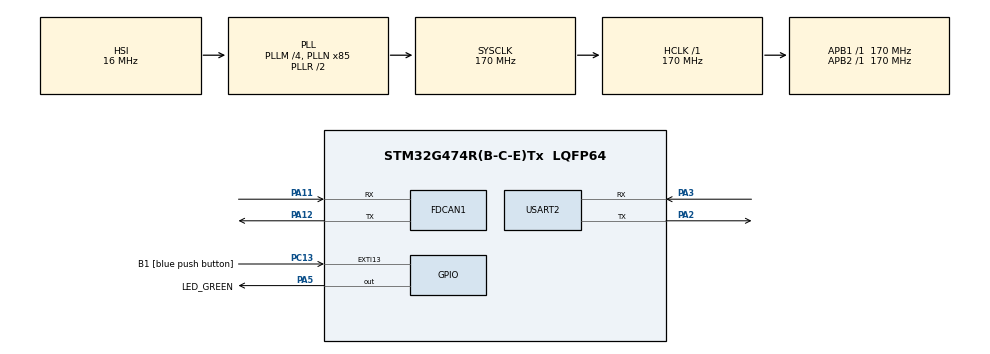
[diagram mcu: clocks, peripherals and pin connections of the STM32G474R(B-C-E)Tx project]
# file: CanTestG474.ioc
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FDCAN1.CalculateBaudRateNominal=100117
FDCAN1.CalculateTimeBitNominal=9988
FDCAN1.CalculateTimeQuantumNominal=3329.4117647058824
FDCAN1.ClockDivider=FDCAN_CLOCK_DIV2
FDCAN1.NominalPrescaler=283
FREERTOS.Tasks01=defaultTask,24,128,StartDefaultTask,Default,NULL,Dynamic,NULL,NULL
Mcu.Family=STM32G4
Mcu.Name=STM32G474R(B-C-E)Tx
Mcu.Package=LQFP64
NVIC.EXTI15_10_IRQn=true\:5\:0\:false\:false\:true\:true\:true\:true\:true
NVIC.FDCAN1_IT0_IRQn=true\:5\:0\:false\:false\:true\:true\:true\:true\:true
NVIC.FDCAN1_IT1_IRQn=true\:5\:0\:false\:false\:true\:true\:true\:true\:true
NVIC.PriorityGroup=NVIC_PRIORITYGROUP_4
NVIC.TIM6_DAC_IRQn=true\:15\:0\:false\:false\:true\:false\:false\:true\:true
NVIC.TimeBase=TIM6_DAC_IRQn
NVIC.TimeBaseIP=TIM6
PA11.GPIO_PuPd=GPIO_PULLUP
PA11.GPIO_Speed=GPIO_SPEED_FREQ_VERY_HIGH
PA11.Mode=FDCAN_Activate
PA11.Signal=FDCAN1_RX
PA12.GPIO_PuPd=GPIO_PULLUP
PA12.GPIO_Speed=GPIO_SPEED_FREQ_VERY_HIGH
PA12.Mode=FDCAN_Activate
PA12.Signal=FDCAN1_TX
PA13.GPIO_Label=T_SWDIO
PA13.Mode=Trace_Asynchronous_SW
PA13.Signal=SYS_JTMS-SWDIO
PA14.GPIO_Label=T_SWCLK
PA14.Mode=Trace_Asynchronous_SW
PA14.Signal=SYS_JTCK-SWCLK
PA2.Mode=Asynchronous
PA2.Signal=USART2_TX
PA3.Mode=Asynchronous
PA3.Signal=USART2_RX
PA5.GPIO_Label=LED_GREEN
PA5.Signal=GPIO_Output
PB3.GPIO_Label=T_SWO
PB3.Mode=Trace_Asynchronous_SW
PB3.Signal=SYS_JTDO-SWO
PC13.GPIO_Label=B1 [blue push button]
PC13.Signal=GPXTI13
PC14-OSC32_IN.GPIO_Label=RCC_OSC32_IN
PC14-OSC32_IN.Signal=RCC_OSC32_IN
PC15-OSC32_OUT.GPIO_Label=RCC_OSC32_OUT
PC15-OSC32_OUT.Signal=RCC_OSC32_OUT
PF0-OSC_IN.GPIO_Label=RCC_OSC_IN
PF0-OSC_IN.Signal=RCC_OSC_IN
PF1-OSC_OUT.GPIO_Label=RCC_OSC_OUT
PF1-OSC_OUT.Signal=RCC_OSC_OUT
ProjectManager.HeapSize=0x200
ProjectManager.StackSize=0x400
ProjectManager.TargetToolchain=STM32CubeIDE
RCC.ADC12Freq_Value=170000000
RCC.ADC345Freq_Value=170000000
RCC.AHBFreq_Value=170000000
RCC.APB1Freq_Value=170000000
RCC.APB1TimFreq_Value=170000000
RCC.APB2Freq_Value=170000000
RCC.APB2TimFreq_Value=170000000
RCC.CortexFreq_Value=170000000
RCC.EXTERNAL_CLOCK_VALUE=12288000
RCC.HCLKFreq_Value=170000000
RCC.HSE_VALUE=24000000
RCC.HSI48_VALUE=48000000
RCC.HSI_VALUE=16000000
RCC.LSE_VALUE=32768
RCC.PLLM=RCC_PLLM_DIV4
RCC.PLLN=85
RCC.RTCClockSelection=RCC_RTCCLKSOURCE_LSE
RCC.SYSCLKFreq_VALUE=170000000
RCC.SYSCLKSource=RCC_SYSCLKSOURCE_PLLCLK
RCC.USBFreq_Value=170000000
RCC.VCOOutputFreq_Value=340000000
USART2.VirtualMode-Asynchronous=VM_ASYNC
VP_FREERTOS_VS_CMSIS_V2.Mode=CMSIS_V2
VP_SYS_VS_DBSignals.Mode=DisableDeadBatterySignals
VP_SYS_VS_tim6.Mode=TIM6
board=NUCLEO-G474RE

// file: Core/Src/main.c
/* USER CODE BEGIN Header */
/**
  ******************************************************************************
  * @file           : main.c
  * @brief          : Main program body
  ******************************************************************************
  * @attention
  *
  * Copyright (c) 2024 STMicroelectronics.
  * All rights reserved.
  *
  * This software is licensed under terms that can be found in the LICENSE file
  * in the root directory of this software component.
  * If no LICENSE file comes with this software, it is provided AS-IS.
  *
  ******************************************************************************
  */
/* USER CODE END Header */
#include "main.h"
#include "cmsis_os.h"

/* USER CODE BEGIN Includes */

#include <stdio.h>
#include <string.h>

/* USER CODE END Includes */

FDCAN_HandleTypeDef hfdcan1;

UART_HandleTypeDef huart2;

/* Definitions for defaultTask */
osThreadId_t defaultTaskHandle;
const osThreadAttr_t defaultTask_attributes = {
  .name = "defaultTask",
  .priority = (osPriority_t) osPriorityNormal,
  .stack_size = 128 * 4
};

void SystemClock_Config(void);
static void MX_GPIO_Init(void);
static void MX_FDCAN1_Init(void);
static void MX_USART2_UART_Init(void);
void StartDefaultTask(void *argument);

/* USER CODE BEGIN 0 */

int _write(int file, char *data, int len)
{
	HAL_UART_Transmit(&huart2, (uint8_t*)data, len, 100);
	return len;
}

/* USER CODE END 0 */

int main(void)
{

  /* MCU Configuration--------------------------------------------------------*/

  /* Reset of all peripherals, Initializes the Flash interface and the Systick. */
  HAL_Init();

  /* Configure the system clock */
  SystemClock_Config();

  /* Initialize all configured peripherals */
  MX_GPIO_Init();
  MX_FDCAN1_Init();
  MX_USART2_UART_Init();

  /* Init scheduler */
  osKernelInitialize();

  /* Create the thread(s) */
  /* creation of defaultTask */
  defaultTaskHandle = osThreadNew(StartDefaultTask, NULL, &defaultTask_attributes);

  /* Start scheduler */
  osKernelStart();

  /* We should never get here as control is now taken by the scheduler */

  /* Infinite loop */
  while (1)
  {

  }
}

void SystemClock_Config(void)
{
  RCC_OscInitTypeDef RCC_OscInitStruct = {0};
  RCC_ClkInitTypeDef RCC_ClkInitStruct = {0};

  /** Configure the main internal regulator output voltage
  */
  HAL_PWREx_ControlVoltageScaling(PWR_REGULATOR_VOLTAGE_SCALE1_BOOST);

  /** Initializes the RCC Oscillators according to the specified parameters
  * in the RCC_OscInitTypeDef structure.
  */
  RCC_OscInitStruct.OscillatorType = RCC_OSCILLATORTYPE_HSI;
  RCC_OscInitStruct.HSIState = RCC_HSI_ON;
  RCC_OscInitStruct.HSICalibrationValue = RCC_HSICALIBRATION_DEFAULT;
  RCC_OscInitStruct.PLL.PLLState = RCC_PLL_ON;
  RCC_OscInitStruct.PLL.PLLSource = RCC_PLLSOURCE_HSI;
  RCC_OscInitStruct.PLL.PLLM = RCC_PLLM_DIV4;
  RCC_OscInitStruct.PLL.PLLN = 85;
  RCC_OscInitStruct.PLL.PLLP = RCC_PLLP_DIV2;
  RCC_OscInitStruct.PLL.PLLQ = RCC_PLLQ_DIV2;
  RCC_OscInitStruct.PLL.PLLR = RCC_PLLR_DIV2;
  if (HAL_RCC_OscConfig(&RCC_OscInitStruct) != HAL_OK)
  {
    Error_Handler();
  }

  /** Initializes the CPU, AHB and APB buses clocks
  */
  RCC_ClkInitStruct.ClockType = RCC_CLOCKTYPE_HCLK|RCC_CLOCKTYPE_SYSCLK
                              |RCC_CLOCKTYPE_PCLK1|RCC_CLOCKTYPE_PCLK2;
  RCC_ClkInitStruct.SYSCLKSource = RCC_SYSCLKSOURCE_PLLCLK;
  RCC_ClkInitStruct.AHBCLKDivider = RCC_SYSCLK_DIV1;
  RCC_ClkInitStruct.APB1CLKDivider = RCC_HCLK_DIV1;
  RCC_ClkInitStruct.APB2CLKDivider = RCC_HCLK_DIV1;

  if (HAL_RCC_ClockConfig(&RCC_ClkInitStruct, FLASH_LATENCY_4) != HAL_OK)
  {
    Error_Handler();
  }
}

static void MX_FDCAN1_Init(void)
{

  hfdcan1.Instance = FDCAN1;
  hfdcan1.Init.ClockDivider = FDCAN_CLOCK_DIV2;
  hfdcan1.Init.FrameFormat = FDCAN_FRAME_CLASSIC;
  hfdcan1.Init.Mode = FDCAN_MODE_NORMAL;
  hfdcan1.Init.AutoRetransmission = DISABLE;
  hfdcan1.Init.TransmitPause = DISABLE;
  hfdcan1.Init.ProtocolException = DISABLE;
  hfdcan1.Init.NominalPrescaler = 283;
  hfdcan1.Init.NominalSyncJumpWidth = 1;
  hfdcan1.Init.NominalTimeSeg1 = 1;
  hfdcan1.Init.NominalTimeSeg2 = 1;
  hfdcan1.Init.DataPrescaler = 1;
  hfdcan1.Init.DataSyncJumpWidth = 1;
  hfdcan1.Init.DataTimeSeg1 = 1;
  hfdcan1.Init.DataTimeSeg2 = 1;
  hfdcan1.Init.StdFiltersNbr = 0;
  hfdcan1.Init.ExtFiltersNbr = 0;
  hfdcan1.Init.TxFifoQueueMode = FDCAN_TX_FIFO_OPERATION;
  if (HAL_FDCAN_Init(&hfdcan1) != HAL_OK)
  {
    Error_Handler();
  }
  /* USER CODE BEGIN FDCAN1_Init 2 */

  FDCAN_FilterTypeDef canFilterConfig;
  canFilterConfig.IdType = FDCAN_STANDARD_ID;
  canFilterConfig.FilterIndex = 0;
  canFilterConfig.FilterType = FDCAN_FILTER_RANGE;
  canFilterConfig.FilterConfig = FDCAN_FILTER_TO_RXFIFO0;
  canFilterConfig.FilterID1 = 0x000;
  canFilterConfig.FilterID2 = 0x010;

  if (HAL_FDCAN_ConfigFilter(&hfdcan1, &canFilterConfig) != HAL_OK)
  {
	  Error_Handler();
  }

  /* USER CODE END FDCAN1_Init 2 */

}

static void MX_USART2_UART_Init(void)
{

  huart2.Instance = USART2;
  huart2.Init.BaudRate = 115200;
  huart2.Init.WordLength = UART_WORDLENGTH_8B;
  huart2.Init.StopBits = UART_STOPBITS_1;
  huart2.Init.Parity = UART_PARITY_NONE;
  huart2.Init.Mode = UART_MODE_TX_RX;
  huart2.Init.HwFlowCtl = UART_HWCONTROL_NONE;
  huart2.Init.OverSampling = UART_OVERSAMPLING_16;
  huart2.Init.OneBitSampling = UART_ONE_BIT_SAMPLE_DISABLE;
  huart2.Init.ClockPrescaler = UART_PRESCALER_DIV1;
  huart2.AdvancedInit.AdvFeatureInit = UART_ADVFEATURE_NO_INIT;
  if (HAL_UART_Init(&huart2) != HAL_OK)
  {
    Error_Handler();
  }
  if (HAL_UARTEx_SetTxFifoThreshold(&huart2, UART_TXFIFO_THRESHOLD_1_8) != HAL_OK)
  {
    Error_Handler();
  }
  if (HAL_UARTEx_SetRxFifoThreshold(&huart2, UART_RXFIFO_THRESHOLD_1_8) != HAL_OK)
  {
    Error_Handler();
  }
  if (HAL_UARTEx_DisableFifoMode(&huart2) != HAL_OK)
  {
    Error_Handler();
  }

}

static void MX_GPIO_Init(void)
{
  GPIO_InitTypeDef GPIO_InitStruct = {0};

  /* GPIO Ports Clock Enable */
  __HAL_RCC_GPIOC_CLK_ENABLE();
  __HAL_RCC_GPIOF_CLK_ENABLE();
  __HAL_RCC_GPIOA_CLK_ENABLE();
  __HAL_RCC_GPIOB_CLK_ENABLE();

  /*Configure GPIO pin Output Level */
  HAL_GPIO_WritePin(LED_GREEN_GPIO_Port, LED_GREEN_Pin, GPIO_PIN_RESET);

  /*Configure GPIO pin : B1_Pin */
  GPIO_InitStruct.Pin = B1_Pin;
  GPIO_InitStruct.Mode = GPIO_MODE_IT_RISING;
  GPIO_InitStruct.Pull = GPIO_NOPULL;
  HAL_GPIO_Init(B1_GPIO_Port, &GPIO_InitStruct);

  /*Configure GPIO pin : LED_GREEN_Pin */
  GPIO_InitStruct.Pin = LED_GREEN_Pin;
  GPIO_InitStruct.Mode = GPIO_MODE_OUTPUT_PP;
  GPIO_InitStruct.Pull = GPIO_NOPULL;
  GPIO_InitStruct.Speed = GPIO_SPEED_FREQ_LOW;
  HAL_GPIO_Init(LED_GREEN_GPIO_Port, &GPIO_InitStruct);

  /* EXTI interrupt init*/
  HAL_NVIC_SetPriority(EXTI15_10_IRQn, 5, 0);
  HAL_NVIC_EnableIRQ(EXTI15_10_IRQn);

}

void StartDefaultTask(void *argument)
{
  /* USER CODE BEGIN 5 */
	FDCAN_TxHeaderTypeDef txHeader;
	txHeader.Identifier = 0x006;
	txHeader.IdType = FDCAN_STANDARD_ID;
	txHeader.TxFrameType = FDCAN_DATA_FRAME;
	txHeader.DataLength = FDCAN_DLC_BYTES_8;
	txHeader.ErrorStateIndicator = FDCAN_ESI_ACTIVE;
	txHeader.BitRateSwitch = FDCAN_BRS_OFF;
	txHeader.FDFormat = FDCAN_CLASSIC_CAN;
	txHeader.TxEventFifoControl = FDCAN_NO_TX_EVENTS;
	txHeader.MessageMarker = 0;

	uint8_t txData[8] = {'C', 'A', 'N', ' ', 'm', 'e', 's', 'g'};

	if (HAL_FDCAN_Start(&hfdcan1) != HAL_OK)
	{
		Error_Handler();
	}

	printf("CANFD tx polling example CMSIS OS2\r\n");

	/* Infinite loop */
	for(;;)
	{
		if (HAL_FDCAN_AddMessageToTxFifoQ(&hfdcan1, &txHeader, txData) == HAL_OK)
		{
			while (HAL_FDCAN_GetTxFifoFreeLevel(&hfdcan1) == 0)
			{
				// Wait for the Tx FIFO to have free space
			}
			osDelay(100);
		}
		else
		{
			Error_Handler();
		}
	}
}

void HAL_TIM_PeriodElapsedCallback(TIM_HandleTypeDef *htim)
{
  if (htim->Instance == TIM6) {
    HAL_IncTick();
  }
}

void Error_Handler(void)
{
  __disable_irq();
  while (1)
  {
  }
}
